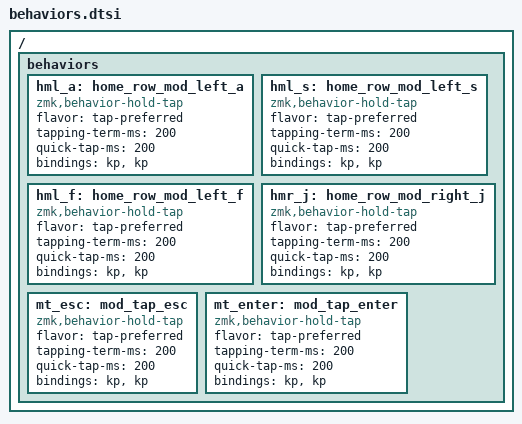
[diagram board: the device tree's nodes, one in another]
/*
 * Custom Behaviors - Tap-preferred with quick-tap
 */

/ {
    behaviors {
        // A key: Left Alt
        hml_a: home_row_mod_left_a {
            compatible = "zmk,behavior-hold-tap";
            #binding-cells = <2>;
            flavor = "tap-preferred";
            tapping-term-ms = <200>;
            quick-tap-ms = <200>;
            bindings = <&kp>, <&kp>;
        };

        // S key: Left Shift
        hml_s: home_row_mod_left_s {
            compatible = "zmk,behavior-hold-tap";
            #binding-cells = <2>;
            flavor = "tap-preferred";
            tapping-term-ms = <200>;
            quick-tap-ms = <200>;
            bindings = <&kp>, <&kp>;
        };

        // F key: Left Control
        hml_f: home_row_mod_left_f {
            compatible = "zmk,behavior-hold-tap";
            #binding-cells = <2>;
            flavor = "tap-preferred";
            tapping-term-ms = <200>;
            quick-tap-ms = <200>;
            bindings = <&kp>, <&kp>;
        };

        // J key: Right Control
        hmr_j: home_row_mod_right_j {
            compatible = "zmk,behavior-hold-tap";
            #binding-cells = <2>;
            flavor = "tap-preferred";
            tapping-term-ms = <200>;
            quick-tap-ms = <200>;
            bindings = <&kp>, <&kp>;
        };

        // ESC key: Left GUI when held
        mt_esc: mod_tap_esc {
            compatible = "zmk,behavior-hold-tap";
            #binding-cells = <2>;
            flavor = "tap-preferred";
            tapping-term-ms = <200>;
            quick-tap-ms = <200>;
            bindings = <&kp>, <&kp>;
        };

        // ENTER key: Right GUI when held
        mt_enter: mod_tap_enter {
            compatible = "zmk,behavior-hold-tap";
            #binding-cells = <2>;
            flavor = "tap-preferred";
            tapping-term-ms = <200>;
            quick-tap-ms = <200>;
            bindings = <&kp>, <&kp>;
        };
    };
};
